# STM32H5E5xx register map
File version: 1.0
Registers are 32-bit, read-write, reset 0x0 unless marked. A register's access mark holds for its fields unless they carry their own. Offsets are from the block's base; [hi:lo] are bit positions; {n}, {i} and the like mark numbered series.

## PKA
Base 0x420C2000
Same registers: PKA_S 0x520C2000
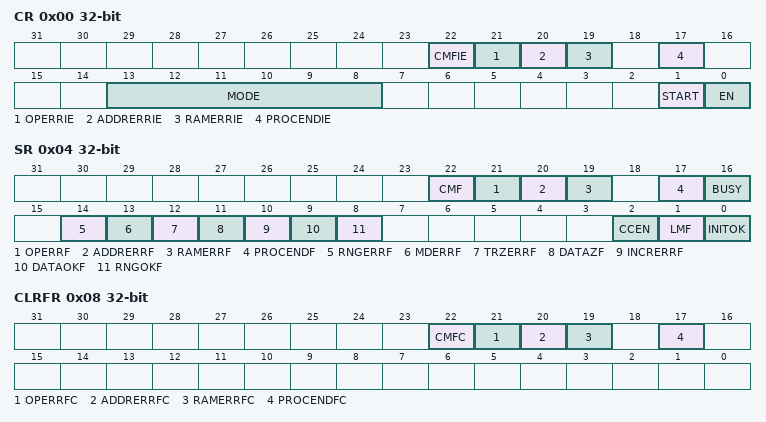
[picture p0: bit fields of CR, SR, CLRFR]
0x00 CR — PKA control register
  [22] CMFIE
  [21] OPERRIE — Operation Error interrupt enable
  [20] ADDRERRIE — Address error interrupt enable
  [19] RAMERRIE — RAM error interrupt enable
  [17] PROCENDIE — End of operation interrupt enable
  [13:8] MODE — MODE[5:0] PKA operation code
  [1] START — Start operation
  [0] EN — PKA enable
0x04 SR — PKA status register
  [22] CMF — Chaining mode flag
  [21] OPERRF — PKA operation Error flag
  [20] ADDRERRF — Address error flag
  [19] RAMERRF — PKA RAM error flag
  [17] PROCENDF — PKA end of operation flag
  [16] BUSY — PKA operation is in progress
  [14] RNGERRF — PKA RNG error flag
  [13] MDERRF — PKA Mode error flag
  [12] TRZERRF — PKA Trailing zeros error flag
  [11] DATAZF — PKA Data zeroed error flag
  [10] INCRERRF — PKA Increment error flag
  [9] DATAOKF — PKA Data OK flag
  [8] RNGOKF — PKA RNG OK flag
  [2] CCEN — PKA Coupling and chaining mode enable
  [1] LMF — PKA Limited mode flag
  [0] INITOK — PKA initialisation flag
0x08 CLRFR — PKA clear flag register
  [22] CMFC — Clear chaining mode flag
  [21] OPERRFC — Clear PKA operation Error flag
  [20] ADDRERRFC — Clear address error flag
  [19] RAMERRFC — Clear PKA RAM error flag
  [17] PROCENDFC — Clear PKA end of operation flag
{0x400+4i} RAM[{i}] (i=0..1333)

## VREFBUF
Base 0x44007400
Same registers: VREFBUF_S 0x54007400
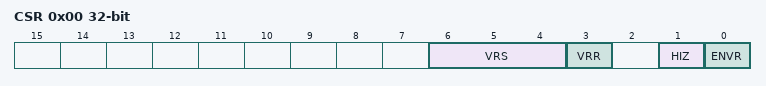
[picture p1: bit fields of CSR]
0x00 CSR — VREFBUF control and status register
  [6:4] VRS — Voltage reference scale
    {v}=SCALE{v} (Voltage reference scale {v} (VREF_OUT{v+1})) (v=0..3)
  [3] VRR — Voltage reference buffer ready
  [1] HIZ — High impedance mode
  [0] ENVR — Voltage reference buffer enable
0x04 CCR — VREFBUF calibration and control register
  [5:0] TRIM — TRIM[5:0] bits (Trimming code)

## PLAY1 — Programmable Logic Array (PLAY)
Base 0x44008000
Same registers: PLAY1_S 0x54008000
0x00 CFGCR — PLAY Configuration Control Register
  [0] UNLOCK — Unlock configuration
0x04 SECCFGR — PLAY Security attributes Configuration Register
  [1:0] SEC — Security configuration
    1=SEC_ITEM_CONFIG (PLAY configuration registers items); 3=SEC_ITEM_ALL (All PLAY registers items); 0=ATTR_NSEC (Non-secure attribute)
0x08 PRIVCFGR — PLAY Privilege attributes Configuration Register
  [1:0] PRIV — Privilege configuration
    1=PRIV_ITEM_CONFIG (PLAY configuration registers items); 3=PRIV_ITEM_ALL (All PLAY registers items); 0=ATTR_NPRIV (Non-privileged attribute)
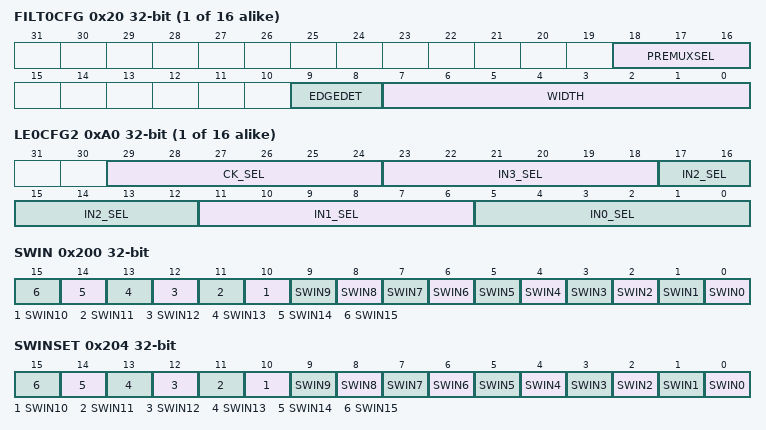
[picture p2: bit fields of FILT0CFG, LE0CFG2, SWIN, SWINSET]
{0x20+4i} FILT{i}CFG (i=0..15) — PLAY Filter Configuration Registers
  [18:16] PREMUXSEL — Input Pre-Multiplexer Selection
  [9:8] EDGEDET — Edge Detection mode
  [7:0] WIDTH — Minimum Pulse Width
    {v}=IN{v} (Input {v}) (v=0..15)
{0x60+4i} LE{i}CFG1 (i=0..15) — PLAY Logic Element Configuration Registers 1
  [15:0] LUT — Look-Up Table contents
    {v}=Lookup table {v} (v=0..15)
{0xA0+4i} LE{i}CFG2 (i=0..15) — PLAY Logic Element Configuration Registers 2
  [29:24] CK_SEL — Clock Enable Selection
  [6n+5:6n] IN{n}_SEL (n=0..3) — Logic Element Input {n}
{0x100+4i} OUT{i}CFG (i=0..15) — PLAY Output Configuration Registers
  [4:0] SEL — Output source Selection
0x200 SWIN — PLAY Software Input Status Register
  [n] SWIN{n} (n=0..15) — Input SWIN{n} state
0x204 SWINSET — PLAY Software Input Set Register
  [n] SWIN{n} (n=0..15) — Set SWIN{n} input
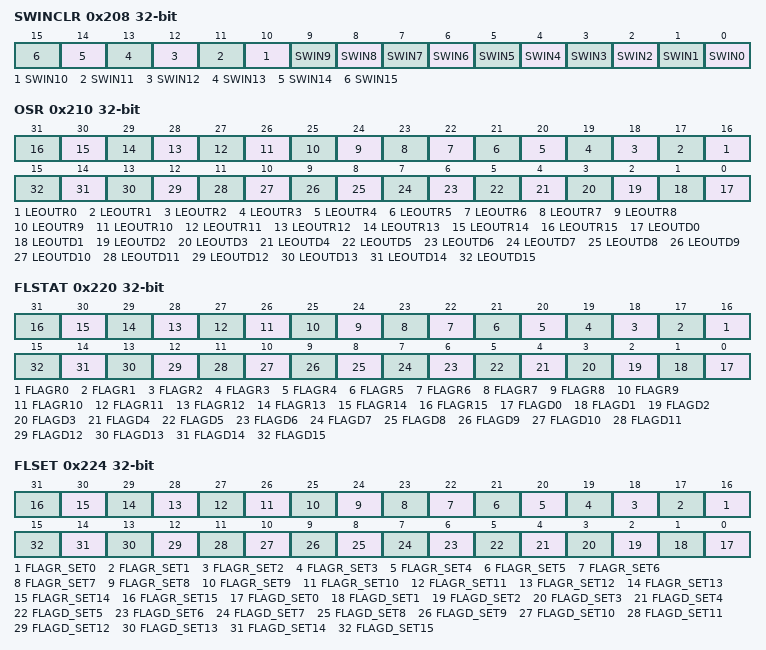
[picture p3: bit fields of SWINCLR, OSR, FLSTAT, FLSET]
0x208 SWINCLR — PLAY Software Input Clear Register
  [n] SWIN{n} (n=0..15) — Reset SWIN{n} input
0x210 OSR — PLAY Output Status Register
  [n+16] LEOUTR{n} (n=0..15) — LEOUTR{n} output
  [n] LEOUTD{n} (n=0..15) — LEOUTD{n} output
0x220 FLSTAT — PLAY Flag Status Register
  [n+16] FLAGR{n} (n=0..15) — Flag Output Register {n}
  [n] FLAGD{n} (n=0..15) — Flag Output Direct{n}
0x224 FLSET — PLAY Flag Set Register
  [n+16] FLAGR_SET{n} (n=0..15) — Flag Output Register {n}
  [n] FLAGD_SET{n} (n=0..15) — Flag Output Direct{n}
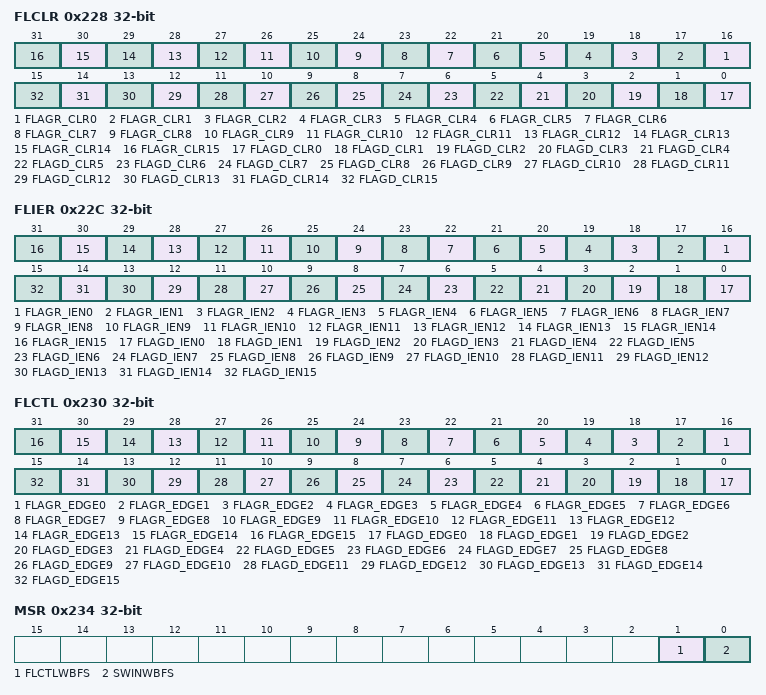
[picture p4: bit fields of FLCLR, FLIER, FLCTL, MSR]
0x228 FLCLR — PLAY Flag Clear Register
  [n+16] FLAGR_CLR{n} (n=0..15) — Flag Output Register {n}
  [n] FLAGD_CLR{n} (n=0..15) — Flag Output Direct{n}
0x22C FLIER — PLAY Flag Interrupt Enable Register
  [n+16] FLAGR_IEN{n} (n=0..15) — Flag Interrupt Output Register {n}
  [n] FLAGD_IEN{n} (n=0..15) — Flag Interrupt Output Direct{n}
0x230 FLCTL — PLAY Flag Control Register
  [n+16] FLAGR_EDGE{n} (n=0..15) — Edge Direction for Output Register {n}
  [n] FLAGD_EDGE{n} (n=0..15) — Edge Direction for Output Direct{n}
0x234 MSR — PLAY Miscellaneous Status Register
  [1] FLCTLWBFS — FLCTL Register Write Busy Flag Status
  [0] SWINWBFS — SWIN Register Write Busy Flag Status
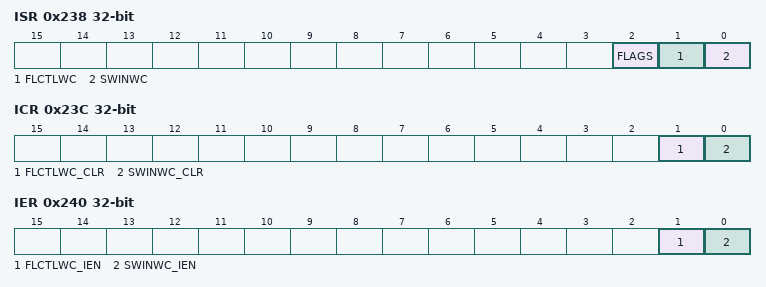
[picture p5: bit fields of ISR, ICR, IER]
0x238 ISR — PLAY Interrupt Status Register
  [2] FLAGS — Flags Interrupt Status
  [1] FLCTLWC — FLCTL Register Write Complete Interrupt Status
  [0] SWINWC — SWIN Register Write Complete Interrupt Status
0x23C ICR — PLAY Interrupt Clear Register
  [1] FLCTLWC_CLR — FLCTL Register Write Complete Clear Interrupt
  [0] SWINWC_CLR — SWIN Register Write Complete Clear Interrupt
0x240 IER — PLAY Interrupt Enable Register
  [1] FLCTLWC_IEN — FLCTL Register Write Complete Interrupt Enable
  [0] SWINWC_IEN — SWIN Register Write Complete Interrupt Enable
